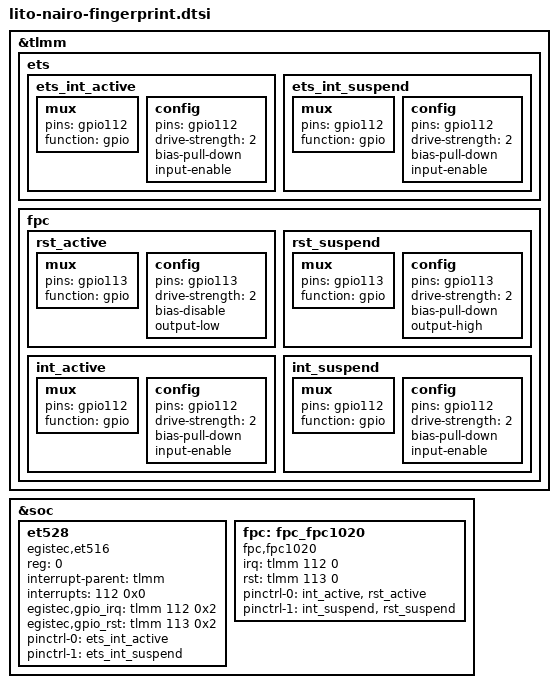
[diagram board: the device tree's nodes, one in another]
&tlmm {
	ets {
		ets_int_active: ets_int_active {
			/* INTERRUPT */
			mux {
				pins = "gpio112";
				function = "gpio";
			};

			config {
				pins = "gpio112";
				drive-strength = <2>; /* 2 MA */
				bias-pull-down; /* pull down */
				input-enable;
			};
		};
		ets_int_suspend: ets_int_suspend {
			/* INTERRUPT */
			mux {
				pins = "gpio112";
				function = "gpio";
			};

			config {
				pins = "gpio112";
				drive-strength = <2>; /* 2 MA */
				bias-pull-down; /* pull down */
				input-enable;
			};
		};
	};

	fpc {
		rst_active: rst_active {
			/* RESET */
			mux {
				pins = "gpio113";
				function = "gpio";
			};
			config {
				pins = "gpio113";
				drive-strength = <2>; /* 2 MA */
				bias-disable;
				output-low;
			};
		};

		rst_suspend: rst_suspend{
			/* RESET */
			mux {
				pins = "gpio113";
				function = "gpio";
			};

			config {
				pins = "gpio113";
				drive-strength = <2>; /* 2 MA */
				bias-pull-down; /* pull down */
				output-high;
			};
		};

		int_active: int_active {
			/* INTERRUPT */
			mux {
				pins = "gpio112";
				function = "gpio";
			};

			config {
				pins = "gpio112";
				drive-strength = <2>; /* 2 MA */
				bias-pull-down; /* pull down */
				input-enable;
			};
		};

		int_suspend: int_suspend{
			/* INTERRUPT */
			mux {
				pins = "gpio112";
				function = "gpio";
			};

			config {
				pins = "gpio112";
				drive-strength = <2>; /* 2 MA */
				bias-pull-down; /* pull down */
				input-enable;
			};
		};
	};
};

&soc {
	et528: et528 {
		compatible = "egistec,et516";
		status = "ok";
		reg = <0>;
		interrupt-parent = <&tlmm>;
		interrupts = <112 0x0>;
		egistec,gpio_irq = <&tlmm 112 0x2>;
		egistec,gpio_rst = <&tlmm 113 0x2>;

		pinctrl-names = "default", "suspend";
		pinctrl-0 = <&ets_int_active>;
		pinctrl-1 = <&ets_int_suspend>;
	};

	fpc: fpc_fpc1020 {
		compatible = "fpc,fpc1020";
		status = "ok";
		irq = <&tlmm 112 0>;
		rst = <&tlmm 113 0>;
		pinctrl-names = "default", "suspend";
		pinctrl-0 = <&int_active &rst_active>;
		pinctrl-1 = < &int_suspend &rst_suspend>;
	};
};
